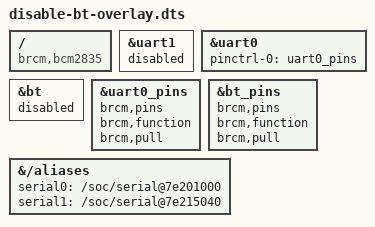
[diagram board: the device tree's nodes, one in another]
/dts-v1/;
/plugin/;

/* Disable Bluetooth and restore UART0/ttyAMA0 over GPIOs 14 & 15.
   To disable the systemd service that initialises the modem so it doesn't use
   the UART:

       sudo systemctl disable hciuart
*/

#include <dt-bindings/gpio/gpio.h>

/{
	compatible = "brcm,bcm2835";

	fragment@0 {
		target = <&uart1>;
		__overlay__ {
			status = "disabled";
		};
	};

	fragment@1 {
		target = <&uart0>;
		__overlay__ {
			pinctrl-names = "default";
			pinctrl-0 = <&uart0_pins>;
			status = "okay";
		};
	};

	fragment@2 {
		target = <&bt>;
		__overlay__ {
			status = "disabled";
		};
	};

	fragment@3 {
		target = <&uart0_pins>;
		__overlay__ {
			brcm,pins;
			brcm,function;
			brcm,pull;
		};
	};

	fragment@4 {
		target = <&bt_pins>;
		__overlay__ {
			brcm,pins;
			brcm,function;
			brcm,pull;
		};
	};

	fragment@5 {
		target-path = "/aliases";
		__overlay__ {
			serial0 = "/soc/serial@7e201000";
			serial1 = "/soc/serial@7e215040";
		};
	};
};
